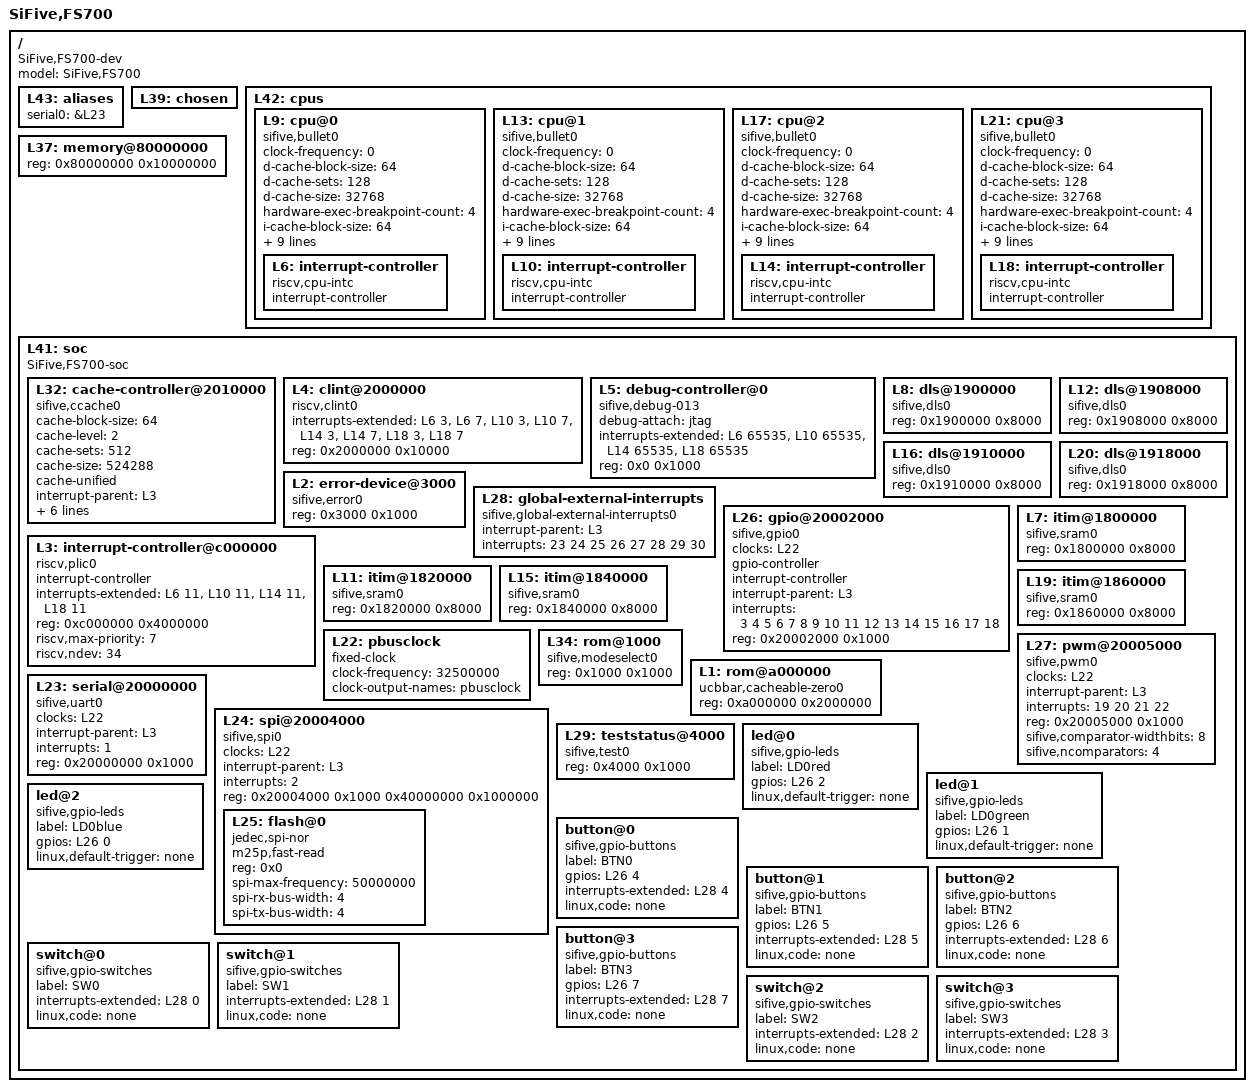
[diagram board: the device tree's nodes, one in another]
/dts-v1/;

/ {
	#address-cells = <1>;
	#size-cells = <1>;
	compatible = "SiFive,FS700-dev", "fs700-dev", "sifive-dev";
	model = "SiFive,FS700";
	L43: aliases {
		serial0 = &L23;
	};
	L39: chosen {
	};
	L42: cpus {
		#address-cells = <1>;
		#size-cells = <0>;
		L9: cpu@0 {
			clock-frequency = <0>;
			compatible = "sifive,bullet0", "riscv";
			d-cache-block-size = <64>;
			d-cache-sets = <128>;
			d-cache-size = <32768>;
			device_type = "cpu";
			hardware-exec-breakpoint-count = <4>;
			i-cache-block-size = <64>;
			i-cache-sets = <128>;
			i-cache-size = <32768>;
			next-level-cache = <&L32>;
			reg = <0x0>;
			riscv,isa = "rv64imafdc";
			riscv,pmpregions = <8>;
			sifive,dls = <&L8>;
			sifive,itim = <&L7>;
			status = "okay";
			timebase-frequency = <32500000>;
			L6: interrupt-controller {
				#interrupt-cells = <1>;
				compatible = "riscv,cpu-intc";
				interrupt-controller;
			};
		};
		L13: cpu@1 {
			clock-frequency = <0>;
			compatible = "sifive,bullet0", "riscv";
			d-cache-block-size = <64>;
			d-cache-sets = <128>;
			d-cache-size = <32768>;
			device_type = "cpu";
			hardware-exec-breakpoint-count = <4>;
			i-cache-block-size = <64>;
			i-cache-sets = <128>;
			i-cache-size = <32768>;
			next-level-cache = <&L32>;
			reg = <0x1>;
			riscv,isa = "rv64imafdc";
			riscv,pmpregions = <8>;
			sifive,dls = <&L12>;
			sifive,itim = <&L11>;
			status = "okay";
			timebase-frequency = <32500000>;
			L10: interrupt-controller {
				#interrupt-cells = <1>;
				compatible = "riscv,cpu-intc";
				interrupt-controller;
			};
		};
		L17: cpu@2 {
			clock-frequency = <0>;
			compatible = "sifive,bullet0", "riscv";
			d-cache-block-size = <64>;
			d-cache-sets = <128>;
			d-cache-size = <32768>;
			device_type = "cpu";
			hardware-exec-breakpoint-count = <4>;
			i-cache-block-size = <64>;
			i-cache-sets = <128>;
			i-cache-size = <32768>;
			next-level-cache = <&L32>;
			reg = <0x2>;
			riscv,isa = "rv64imafdc";
			riscv,pmpregions = <8>;
			sifive,dls = <&L16>;
			sifive,itim = <&L15>;
			status = "okay";
			timebase-frequency = <32500000>;
			L14: interrupt-controller {
				#interrupt-cells = <1>;
				compatible = "riscv,cpu-intc";
				interrupt-controller;
			};
		};
		L21: cpu@3 {
			clock-frequency = <0>;
			compatible = "sifive,bullet0", "riscv";
			d-cache-block-size = <64>;
			d-cache-sets = <128>;
			d-cache-size = <32768>;
			device_type = "cpu";
			hardware-exec-breakpoint-count = <4>;
			i-cache-block-size = <64>;
			i-cache-sets = <128>;
			i-cache-size = <32768>;
			next-level-cache = <&L32>;
			reg = <0x3>;
			riscv,isa = "rv64imafdc";
			riscv,pmpregions = <8>;
			sifive,dls = <&L20>;
			sifive,itim = <&L19>;
			status = "okay";
			timebase-frequency = <32500000>;
			L18: interrupt-controller {
				#interrupt-cells = <1>;
				compatible = "riscv,cpu-intc";
				interrupt-controller;
			};
		};
	};
	L37: memory@80000000 {
		device_type = "memory";
		reg = <0x80000000 0x10000000>;
	};
	L41: soc {
		#address-cells = <1>;
		#size-cells = <1>;
		compatible = "SiFive,FS700-soc", "fs700-soc", "sifive-soc", "simple-bus";
		ranges;
		L32: cache-controller@2010000 {
			cache-block-size = <64>;
			cache-level = <2>;
			cache-sets = <512>;
			cache-size = <524288>;
			cache-unified;
			compatible = "sifive,ccache0", "cache";
			interrupt-parent = <&L3>;
			interrupts = <31 32 33 34>;
			next-level-cache = <&L1 &L37>;
			reg = <0x2010000 0x1000 0x8000000 0x80000>;
			reg-names = "control", "sideband";
			sifive,a-mshr-count = <6>;
			sifive,bank-count = <2>;
			sifive,ecc-granularity = <8>;
		};
		L4: clint@2000000 {
			compatible = "riscv,clint0";
			interrupts-extended = <&L6 3 &L6 7 &L10 3 &L10 7 &L14 3 &L14 7 &L18 3 &L18 7>;
			reg = <0x2000000 0x10000>;
			reg-names = "control";
		};
		L5: debug-controller@0 {
			compatible = "sifive,debug-013", "riscv,debug-013";
			debug-attach = "jtag";
			interrupts-extended = <&L6 65535 &L10 65535 &L14 65535 &L18 65535>;
			reg = <0x0 0x1000>;
			reg-names = "control";
		};
		L8: dls@1900000 {
			compatible = "sifive,dls0";
			reg = <0x1900000 0x8000>;
			reg-names = "mem";
		};
		L12: dls@1908000 {
			compatible = "sifive,dls0";
			reg = <0x1908000 0x8000>;
			reg-names = "mem";
		};
		L16: dls@1910000 {
			compatible = "sifive,dls0";
			reg = <0x1910000 0x8000>;
			reg-names = "mem";
		};
		L20: dls@1918000 {
			compatible = "sifive,dls0";
			reg = <0x1918000 0x8000>;
			reg-names = "mem";
		};
		L2: error-device@3000 {
			compatible = "sifive,error0";
			reg = <0x3000 0x1000>;
		};
		L28: global-external-interrupts {
			compatible = "sifive,global-external-interrupts0";
			interrupt-parent = <&L3>;
			interrupts = <23 24 25 26 27 28 29 30>;
		};
		L26: gpio@20002000 {
			#gpio-cells = <2>;
			#interrupt-cells = <2>;
			clocks = <&L22>;
			compatible = "sifive,gpio0", "sifive,gpio1";
			gpio-controller;
			interrupt-controller;
			interrupt-parent = <&L3>;
			interrupts = <3 4 5 6 7 8 9 10 11 12 13 14 15 16 17 18>;
			reg = <0x20002000 0x1000>;
			reg-names = "control";
		};
		L3: interrupt-controller@c000000 {
			#interrupt-cells = <1>;
			compatible = "riscv,plic0";
			interrupt-controller;
			interrupts-extended = <&L6 11 &L10 11 &L14 11 &L18 11>;
			reg = <0xc000000 0x4000000>;
			reg-names = "control";
			riscv,max-priority = <7>;
			riscv,ndev = <34>;
		};
		L7: itim@1800000 {
			compatible = "sifive,sram0";
			reg = <0x1800000 0x8000>;
			reg-names = "mem";
		};
		L11: itim@1820000 {
			compatible = "sifive,sram0";
			reg = <0x1820000 0x8000>;
			reg-names = "mem";
		};
		L15: itim@1840000 {
			compatible = "sifive,sram0";
			reg = <0x1840000 0x8000>;
			reg-names = "mem";
		};
		L19: itim@1860000 {
			compatible = "sifive,sram0";
			reg = <0x1860000 0x8000>;
			reg-names = "mem";
		};
		L22: pbusclock {
			#clock-cells = <0>;
			clock-frequency = <32500000>;
			clock-output-names = "pbusclock";
			compatible = "fixed-clock";
		};
		L27: pwm@20005000 {
			clocks = <&L22>;
			compatible = "sifive,pwm0";
			interrupt-parent = <&L3>;
			interrupts = <19 20 21 22>;
			reg = <0x20005000 0x1000>;
			reg-names = "control";
			sifive,comparator-widthbits = <8>;
			sifive,ncomparators = <4>;
		};
		L34: rom@1000 {
			compatible = "sifive,modeselect0";
			reg = <0x1000 0x1000>;
			reg-names = "mem";
		};
		L1: rom@a000000 {
			compatible = "ucbbar,cacheable-zero0";
			reg = <0xa000000 0x2000000>;
		};
		L23: serial@20000000 {
			clocks = <&L22>;
			compatible = "sifive,uart0";
			interrupt-parent = <&L3>;
			interrupts = <1>;
			reg = <0x20000000 0x1000>;
			reg-names = "control";
		};
		L24: spi@20004000 {
			#address-cells = <1>;
			#size-cells = <0>;
			clocks = <&L22>;
			compatible = "sifive,spi0";
			interrupt-parent = <&L3>;
			interrupts = <2>;
			reg = <0x20004000 0x1000 0x40000000 0x1000000>;
			reg-names = "control", "mem";
			L25: flash@0 {
				compatible = "jedec,spi-nor";
				m25p,fast-read;
				reg = <0x0>;
				spi-max-frequency = <50000000>;
				spi-rx-bus-width = <4>;
				spi-tx-bus-width = <4>;
			};
		};
		L29: teststatus@4000 {
			compatible = "sifive,test0";
			reg = <0x4000 0x1000>;
			reg-names = "control";
		};
				led@0 {
						compatible = "sifive,gpio-leds";
						label = "LD0red";
						gpios = <&L26 2>;
						linux,default-trigger = "none";
				};
				led@1 {
						compatible = "sifive,gpio-leds";
						label = "LD0green";
						gpios = <&L26 1>;
						linux,default-trigger = "none";
				};
				led@2 {
						compatible = "sifive,gpio-leds";
						label = "LD0blue";
						gpios = <&L26 0>;
						linux,default-trigger = "none";
				};
				button@0 {
						compatible = "sifive,gpio-buttons";
						label = "BTN0";
						gpios = <&L26 4>;
						interrupts-extended = <&L28 4>;
						linux,code = "none";
				};
				button@1 {
						compatible = "sifive,gpio-buttons";
						label = "BTN1";
						gpios = <&L26 5>;
						interrupts-extended = <&L28 5>;
						linux,code = "none";
				};
				button@2 {
						compatible = "sifive,gpio-buttons";
						label = "BTN2";
						gpios = <&L26 6>;
						interrupts-extended = <&L28 6>;
						linux,code = "none";
				};
				button@3 {
						compatible = "sifive,gpio-buttons";
						label = "BTN3";
						gpios = <&L26 7>;
						interrupts-extended = <&L28 7>;
						linux,code = "none";
				};
				switch@0 {
						compatible = "sifive,gpio-switches";
						label = "SW0";
						interrupts-extended = <&L28 0>;
						linux,code = "none";
				};
				switch@1 {
						compatible = "sifive,gpio-switches";
						label = "SW1";
						interrupts-extended = <&L28 1>;
						linux,code = "none";
				};
				switch@2 {
						compatible = "sifive,gpio-switches";
						label = "SW2";
						interrupts-extended = <&L28 2>;
						linux,code = "none";
				};
				switch@3 {
						compatible = "sifive,gpio-switches";
						label = "SW3";
						interrupts-extended = <&L28 3>;
						linux,code = "none";
				};

	};
};
